# STM32L4x2 register map
File version: 2.3
CPU: CM4 r0p1, little endian, MPU, FPU, 4 interrupt priority bits
Registers are 32-bit, read-write, reset 0x0 unless marked. A register's access mark holds for its fields unless they carry their own. Offsets are from the block's base; [hi:lo] are bit positions; 'fields as' and 'values as' point back to an identical list.

## ADC123_Common — Analog-to-Digital Converter
Base 0x50040300
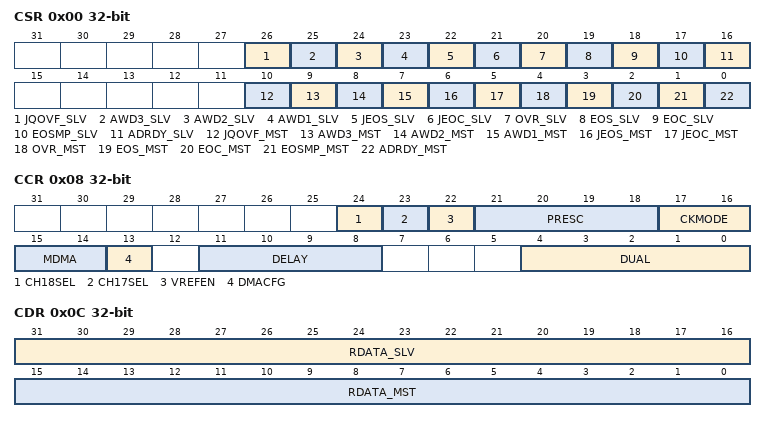
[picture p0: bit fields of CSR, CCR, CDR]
0x00 CSR ro — ADC common status register
  [26] JQOVF_SLV — Injected Context Queue Overflow flag of the slave ADC This bit is a copy of the JQOVF bit in the corresponding ADC_ISR register.
    0=NoOverflow (No injected context queue overflow has occurred); 1=Overflow (Injected context queue overflow has occurred)
  [25] AWD3_SLV — Analog watchdog 3 flag of the slave ADC This bit is a copy of the AWD3 bit in the corresponding ADC_ISR register.
    0=NoEvent (No analog watchdog event occurred); 1=Event (Analog watchdog event occurred)
  [24] AWD2_SLV — Analog watchdog 2 flag of the slave ADC This bit is a copy of the AWD2 bit in the corresponding ADC_ISR register.
    values as AWD3_SLV
  [23] AWD1_SLV — Analog watchdog 1 flag of the slave ADC This bit is a copy of the AWD1 bit in the corresponding ADC_ISR register.
    values as AWD3_SLV
  [22] JEOS_SLV — End of injected sequence flag of the slave ADC This bit is a copy of the JEOS bit in the corresponding ADC_ISR register.
    0=NotComplete (Injected sequence is not complete); 1=Complete (Injected sequence complete)
  [21] JEOC_SLV — End of injected conversion flag of the slave ADC This bit is a copy of the JEOC bit in the corresponding ADC_ISR register.
    0=NotComplete (Injected conversion is not complete); 1=Complete (Injected conversion complete)
  [20] OVR_SLV — Overrun flag of the slave ADC This bit is a copy of the OVR bit in the corresponding ADC_ISR register.
    0=No overrun occurred; 1=Overrun occurred
  [19] EOS_SLV — End of regular sequence flag of the slave ADC. This bit is a copy of the EOS bit in the corresponding ADC_ISR register.
    0=NotComplete (Regular sequence is not complete); 1=Complete (Regular sequence complete)
  [18] EOC_SLV — End of regular conversion of the slave ADC This bit is a copy of the EOC bit in the corresponding ADC_ISR register.
    0=NotComplete (Regular conversion is not complete); 1=Complete (Regular conversion complete)
  [17] EOSMP_SLV — End of Sampling phase flag of the slave ADC This bit is a copy of the EOSMP2 bit in the corresponding ADC_ISR register.
    0=NotEnded (End of sampling phase no yet reached); 1=Ended (End of sampling phase reached)
  [16] ADRDY_SLV — Slave ADC ready This bit is a copy of the ADRDY bit in the corresponding ADC_ISR register.
    0=NotReady (ADC is not ready to start conversion); 1=Ready (ADC is ready to start conversion)
  [10] JQOVF_MST — Injected Context Queue Overflow flag of the master ADC This bit is a copy of the JQOVF bit in the corresponding ADC_ISR register.
    values as JQOVF_SLV
  [9] AWD3_MST — Analog watchdog 3 flag of the master ADC This bit is a copy of the AWD3 bit in the corresponding ADC_ISR register.
    values as AWD3_SLV
  [8] AWD2_MST — Analog watchdog 2 flag of the master ADC This bit is a copy of the AWD2 bit in the corresponding ADC_ISR register.
    values as AWD3_SLV
  [7] AWD1_MST — Analog watchdog 1 flag of the master ADC This bit is a copy of the AWD1 bit in the corresponding ADC_ISR register.
    values as AWD3_SLV
  [6] JEOS_MST — End of injected sequence flag of the master ADC This bit is a copy of the JEOS bit in the corresponding ADC_ISR register.
    values as JEOS_SLV
  [5] JEOC_MST — End of injected conversion flag of the master ADC This bit is a copy of the JEOC bit in the corresponding ADC_ISR register.
    values as JEOC_SLV
  [4] OVR_MST — Overrun flag of the master ADC This bit is a copy of the OVR bit in the corresponding ADC_ISR register.
    0=No overrun occurred; 1=Overrun occurred
  [3] EOS_MST — End of regular sequence flag of the master ADC This bit is a copy of the EOS bit in the corresponding ADC_ISR register.
    values as EOS_SLV
  [2] EOC_MST — End of regular conversion of the master ADC This bit is a copy of the EOC bit in the corresponding ADC_ISR register.
    values as EOC_SLV
  [1] EOSMP_MST — End of Sampling phase flag of the master ADC This bit is a copy of the EOSMP bit in the corresponding ADC_ISR register.
    values as EOSMP_SLV
  [0] ADRDY_MST — Master ADC ready This bit is a copy of the ADRDY bit in the corresponding ADC_ISR register.
    values as ADRDY_SLV
0x08 CCR — ADC common control register
  [24] CH18SEL — CH18 selection This bit is set and cleared by software to control channel 18.
  [23] CH17SEL — CH17 selection This bit is set and cleared by software to control channel 17.
  [22] VREFEN — V<sub>REFINT</sub> enable This bit is set and cleared by software to enable/disable the V<sub>REFINT</sub> channel.
    0=Disabled (V_REFINT channel disabled); 1=Enabled (V_REFINT channel enabled)
  [21:18] PRESC — ADC prescaler These bits are set and cleared by software to select the frequency of the clock to the ADC. The clock is common for all the ADCs. other: reserved Note: The software is allowed to write these bits only when the ADC is disabled (ADCAL = 0, JADSTART = 0, ADSTART = 0, ADSTP = 0, ADDIS = 0 and ADEN = 0). The ADC prescaler value is applied only when CKMODE[1:0] = 00.
  [17:16] CKMODE — ADC clock mode These bits are set and cleared by software to define the ADC clock scheme (which is common to both master and slave ADCs): In all synchronous clock modes, there is no jitter in the delay from a timer trigger to the start of a conversion. Note: The software is allowed to write these bits only when the ADCs are disabled (ADCAL = 0, JADSTART = 0, ADSTART = 0, ADSTP = 0, ADDIS = 0 and ADEN = 0).
    0=Asynchronous (Use Kernel Clock adc_ker_ck_input divided by PRESC. Asynchronous to AHB clock); 1=SyncDiv1 (Use AHB clock rcc_hclk3. In this case rcc_hclk must equal sys_d1cpre_ck); 2=SyncDiv2 (Use AHB clock rcc_hclk3 divided by 2); 3=SyncDiv4 (Use AHB clock rcc_hclk3 divided by 4)
  [15:14] MDMA — Direct memory access mode for dual ADC mode This bitfield is set and cleared by software. Refer to the DMA controller section for more details. Note: The software is allowed to write these bits only when ADSTART = 0 (which ensures that no regular conversion is ongoing).
  [13] DMACFG — DMA configuration (for dual ADC mode) This bit is set and cleared by software to select between two DMA modes of operation and is effective only when DMAEN = 1. For more details, refer to Section : Managing conversions using the DMA Note: The software is allowed to write these bits only when ADSTART = 0 (which ensures that no regular conversion is ongoing).
  [11:8] DELAY — Delay between 2 sampling phases These bits are set and cleared by software. These bits are used in dual interleaved modes. Refer to Table 112 for the value of ADC resolution versus DELAY bits values. Note: The software is allowed to write these bits only when the ADCs are disabled (ADCAL = 0, JADSTART = 0, ADSTART = 0, ADSTP = 0, ADDIS = 0 and ADEN = 0).
  [4:0] DUAL — Dual ADC mode selection These bits are written by software to select the operating mode. All the ADCs independent: 00001 to 01001: Dual mode, master and slave ADCs working together All other combinations are reserved and must not be programmed Note: The software is allowed to write these bits only when the ADCs are disabled (ADCAL = 0, JADSTART = 0, ADSTART = 0, ADSTP = 0, ADDIS = 0 and ADEN = 0).
    0=Independent mode; 1=DualRJ (Dual, combined regular simultaneous + injected simultaneous mode); 2=DualRA (Dual, combined regular simultaneous + alternate trigger mode); 3=DualIJ (Dual, combined interleaved mode + injected simultaneous mode); 5=DualJ (Dual, injected simultaneous mode only); 6=Dual, regular simultaneous mode only; 7=Dual, interleaved mode only; 9=Dual, alternate trigger mode only
0x0C CDR ro — ADC common regular data register for dual mode
  [31:16] RDATA_SLV — Regular data of the slave ADC In dual mode, these bits contain the regular data of the slave ADC. Refer to Section 16.4.32: Dual ADC modes. The data alignment is applied as described in Section : Data register, data alignment and offset (ADC_DR, OFFSETy, OFFSETy_CH, ALIGN))
  [15:0] RDATA_MST — Regular data of the master ADC. In dual mode, these bits contain the regular data of the master ADC. Refer to Section 16.4.32: Dual ADC modes. The data alignment is applied as described in Section : Data register, data alignment and offset (ADC_DR, OFFSETy, OFFSETy_CH, ALIGN)) In MDMA = 11 mode, bits 15:8 contains SLV_ADC_DR[7:0], bits 7:0 contains MST_ADC_DR[7:0].
